# DDR16SS0_CTLPHY_WRAP_CTL_CFG_CTLCFG register map
Vendor: Texas Instruments
Registers are 32-bit, read-write, reset 0x0 unless marked. A register's access mark holds for its fields unless they carry their own. Offsets are as the file gives them; [hi:lo] are bit positions; lines under a group give offsets from that group; {n}, {i} and the like mark numbered series.

## DDR16SS0_CTLPHY_WRAP_CTL_CFG_CTLCFG (part 5 of 9)
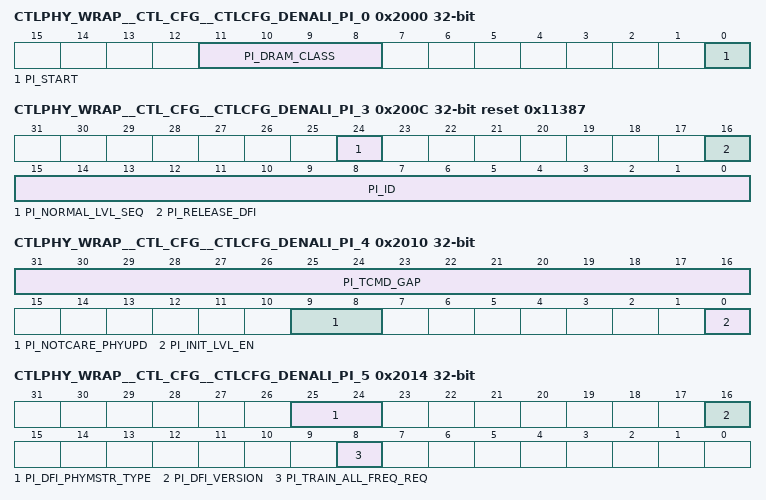
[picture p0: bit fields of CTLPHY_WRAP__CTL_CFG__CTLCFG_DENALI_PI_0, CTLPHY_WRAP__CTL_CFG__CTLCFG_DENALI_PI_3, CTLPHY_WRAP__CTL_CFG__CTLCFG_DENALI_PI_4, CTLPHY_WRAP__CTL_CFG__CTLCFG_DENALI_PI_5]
0x2000 CTLPHY_WRAP__CTL_CFG__CTLCFG_DENALI_PI_0
  [11:8] PI_DRAM_CLASS — Defines the memory class for the PI.
  [0] PI_START — Initiate command processing in the PI. Set to 1 to initiate.
0x2004 CTLPHY_WRAP__CTL_CFG__CTLCFG_DENALI_PI_1 ro reset 0xAE8D79E2
  [31:0] PI_VERSION_0 — Holds the PI version number. This is a unique number for each PHY IP delivery. This will help in identifying different version of the PHY IP. READ-ONLY
0x2008 CTLPHY_WRAP__CTL_CFG__CTLCFG_DENALI_PI_2 ro reset 0x714B570
  [31:0] PI_VERSION_1 — Holds the PI version number. This is a unique number for each PHY IP delivery. This will help in identifying different version of the PHY IP. READ-ONLY
0x200C CTLPHY_WRAP__CTL_CFG__CTLCFG_DENALI_PI_3 access per field reset 0x11387
  [24] PI_NORMAL_LVL_SEQ rw — Enable the PI to finish all the pending leveling before releasing the DFI bus.
  [16] PI_RELEASE_DFI ro — This is a status whether PI has release DFI. READ-ONLY.
  [15:0] PI_ID ro — Holds the PI ID number. This is a Cadence DDR PHY IP identifier. It is set to 0x1387. READ-ONLY
0x2010 CTLPHY_WRAP__CTL_CFG__CTLCFG_DENALI_PI_4
  [31:16] PI_TCMD_GAP — Specifies the minimum gap in DFI clocks between two commands. Used to guard the timing from the last command of MC and the first command of PI when MC hand over the control of DFI to PI.
  [9:8] PI_NOTCARE_PHYUPD — Allow the PI to issue a master request to the controller if a phyupd_req from the PHY has been detected.bit[1] represents supports in normal state;bit[0] represents supports in initialization state. Set to 1 to issue the master request.
  [0] PI_INIT_LVL_EN — Enables the initial leveling sequence after PI initialization procedure. Set to 1 to enable.
0x2014 CTLPHY_WRAP__CTL_CFG__CTLCFG_DENALI_PI_5 access per field
  [25:24] PI_DFI_PHYMSTR_TYPE rw — DFI Master Request Type used for dfi 4.1 verision: This signal indicates the required state of DRAM when PHY becomes the master. Each memory rank uses one bit. 1'b0: IDLE. The MC should close all the pages. 1'b1: IDLE or Self Refresh.
  [16] PI_DFI_VERSION rw — Define the DFI master version, set 1 for DFI4.1, set 0 for DFI4.0
  [8] PI_TRAIN_ALL_FREQ_REQ wo — Triggers training for all supported frequencies in PI_FREQ_MAP. Applies to LPDDR4 devices onlyh. Set to 1 to trigger. Only applicable after memory initialization has been completed. Can be used to train new frequencies that were not available at initialization time. WRITE-ONLY
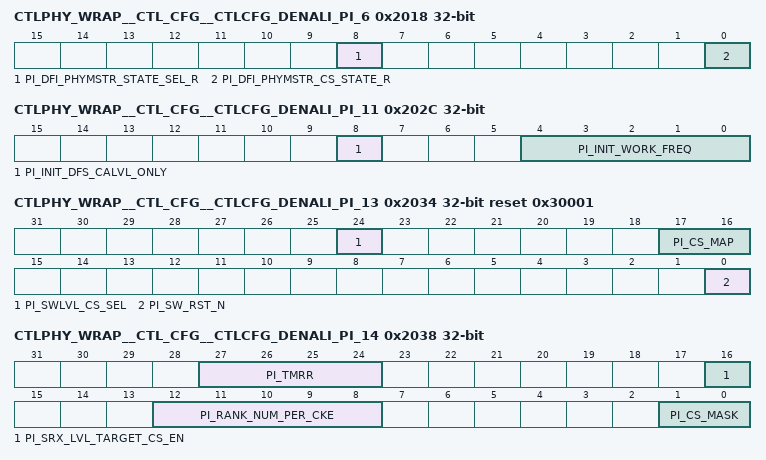
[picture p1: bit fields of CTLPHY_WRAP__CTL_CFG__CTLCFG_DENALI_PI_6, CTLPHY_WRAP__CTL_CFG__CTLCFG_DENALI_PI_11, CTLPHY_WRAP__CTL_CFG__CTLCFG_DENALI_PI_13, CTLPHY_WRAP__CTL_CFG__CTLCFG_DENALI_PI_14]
0x2018 CTLPHY_WRAP__CTL_CFG__CTLCFG_DENALI_PI_6
  [8] PI_DFI_PHYMSTR_STATE_SEL_R — DFI PHY Master State Select: Indication from the PHY to the MC whether the requested memory state is IDLE or Self refresh. 'b0: indicates that the corresponding CS must be put into the IDLE state. 'b1: indicates that the corresponding CS must be put into the Self refresh state.
  [0] PI_DFI_PHYMSTR_CS_STATE_R — This signal indicates the state of the DRAM when the PHY becomes the master. 'b0: The PHY specifies the required state, using the dfi_phymstr_state_sel signal. 'b1: is reserved.
0x201C CTLPHY_WRAP__CTL_CFG__CTLCFG_DENALI_PI_7 ro
  [31:0] PI_TDFI_PHYMSTR_MAX — Indicates the maximum number of DFI clock cycles registered while the dfi_phymstr_req signal is asserted and the dfi_phymstr_ack signal is asserted. READ-ONLY.
0x2020 CTLPHY_WRAP__CTL_CFG__CTLCFG_DENALI_PI_8 ro
  [19:0] PI_TDFI_PHYMSTR_RESP — Indicates the maximum number of DFI clock cycles registered between a dfi_phymstr_req signal assertion and a dfi_phymstr_ack signal assertion. READ-ONLY
0x2024 CTLPHY_WRAP__CTL_CFG__CTLCFG_DENALI_PI_9 ro
  [19:0] PI_TDFI_PHYUPD_RESP — Indicates the maximum number of DFI clock cycles registered between a dfi_phyupd_req signal assertion and a dfi_phyupd_ack signal assertion. READ-ONLY.
0x2028 CTLPHY_WRAP__CTL_CFG__CTLCFG_DENALI_PI_10 ro
  [31:0] PI_TDFI_PHYUPD_MAX — Indicates the maximum number of DFI clock cycles registered while the dfi_phyupd_req signal is asserted and the dfi_phy_ack signal is asserted. READ-ONLY.
0x202C CTLPHY_WRAP__CTL_CFG__CTLCFG_DENALI_PI_11
  [8] PI_INIT_DFS_CALVL_ONLY — Enables frequency training for CA leveling only. Other trainings are not performed.
  [4:0] PI_INIT_WORK_FREQ — Indicates the initial work frequency after initialization and initial leveling sequence.
0x2030 CTLPHY_WRAP__CTL_CFG__CTLCFG_DENALI_PI_12
  [31:0] PI_FREQ_MAP — Frequency map for supported working frequencies. Each bit represents one supported frequency.
0x2034 CTLPHY_WRAP__CTL_CFG__CTLCFG_DENALI_PI_13 reset 0x30001
  [24] PI_SWLVL_CS_SEL — Defines which chip selects are active in swlvl, 0 for binary, 1 for one-hot.
  [17:16] PI_CS_MAP — Defines which chip selects are active.
  [0] PI_SW_RST_N — User request to reset the whole PI except the parameter modules. Set 0 to reset, set to 1 to release.
0x2038 CTLPHY_WRAP__CTL_CFG__CTLCFG_DENALI_PI_14
  [27:24] PI_TMRR — DRAM tMRR value in memory clock cycles.
  [16] PI_SRX_LVL_TARGET_CS_EN — Defines self refresh exit trigger target rank/ranks training or all ranks training. 1: The rank/ranks exit from self refresh will trigger the corresponding rank/ranks training. Note: If multiple ranks exit from self refresh, current design only support the multiple ranks srx command issues at the same time. 0: Any rank/ranks exit from self refresh will trigger all ranks training
  [12:8] PI_RANK_NUM_PER_CKE — Defines the number of chip selects share one cke
  [1:0] PI_CS_MASK — Defines which chip selects are active.
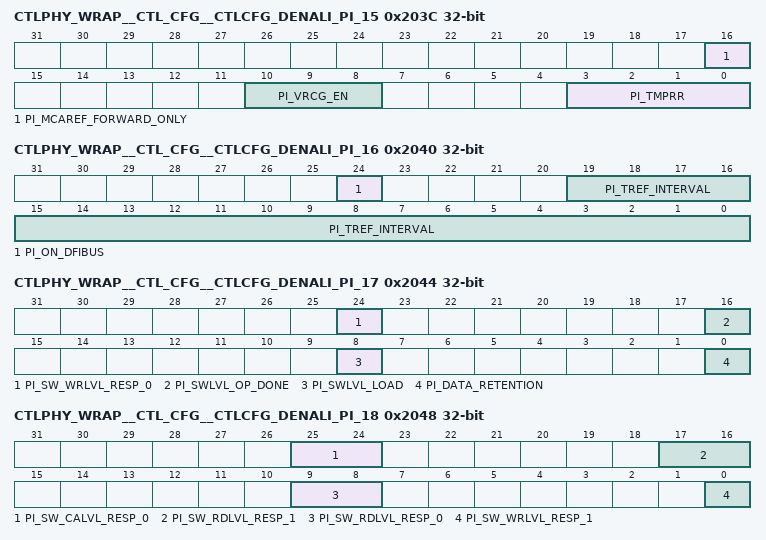
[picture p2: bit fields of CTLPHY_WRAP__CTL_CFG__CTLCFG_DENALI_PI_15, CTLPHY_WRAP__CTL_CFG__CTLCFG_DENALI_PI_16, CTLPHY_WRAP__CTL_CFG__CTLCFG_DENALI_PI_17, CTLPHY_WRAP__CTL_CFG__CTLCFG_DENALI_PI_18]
0x203C CTLPHY_WRAP__CTL_CFG__CTLCFG_DENALI_PI_15
  [16] PI_MCAREF_FORWARD_ONLY — Controls the generation of AREF from the PI module or forward the MC received value.
  [10:8] PI_VRCG_EN — Whether enable VRCG mode in two cases: bit0 - when DFS. bit1-when setting DQ Vref. bit2-when setting CBT.
  [3:0] PI_TMPRR — DRAM tMPRR value in memory clock cycles.
0x2040 CTLPHY_WRAP__CTL_CFG__CTLCFG_DENALI_PI_16 access per field
  [24] PI_ON_DFIBUS ro — Monitors the state of the PI controlling the DFI bus. 1 means PI is in control. READ-ONLY.
  [19:0] PI_TREF_INTERVAL rw — Defines the cycles between refreshes to different chip selects.
0x2044 CTLPHY_WRAP__CTL_CFG__CTLCFG_DENALI_PI_17 access per field
  [24] PI_SW_WRLVL_RESP_0 ro — Write leveling response for data slice 0. READ-ONLY
  [16] PI_SWLVL_OP_DONE ro — Reports the status of the software leveling operation. Value of 1 indicates operation complete. READ-ONLY
  [8] PI_SWLVL_LOAD wo — User request to load delays and execute software leveling. Set to 1 to trigger. WRITE-ONLY
  [0] PI_DATA_RETENTION ro — Monitors the readiness for the PHY to be put into data retention mode after pi_sref_entry req parameter has been written. 1 means ready for data retention. READ-ONLY.
0x2048 CTLPHY_WRAP__CTL_CFG__CTLCFG_DENALI_PI_18 ro
  [25:24] PI_SW_CALVL_RESP_0 — CA leveling response for address slice 0. READ-ONLY
  [17:16] PI_SW_RDLVL_RESP_1 — Read leveling response for data slice 1. READ-ONLY
  [9:8] PI_SW_RDLVL_RESP_0 — Read leveling response for data slice 0. READ-ONLY
  [0] PI_SW_WRLVL_RESP_1 — Write leveling response for data slice 1. READ-ONLY
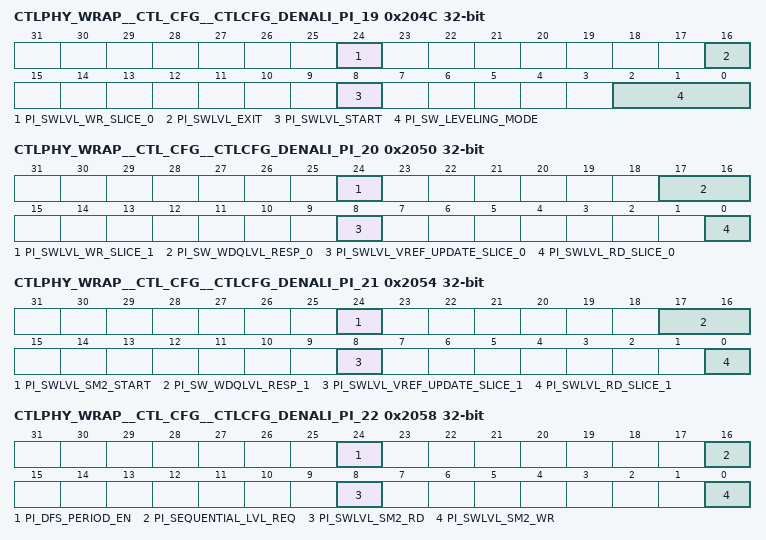
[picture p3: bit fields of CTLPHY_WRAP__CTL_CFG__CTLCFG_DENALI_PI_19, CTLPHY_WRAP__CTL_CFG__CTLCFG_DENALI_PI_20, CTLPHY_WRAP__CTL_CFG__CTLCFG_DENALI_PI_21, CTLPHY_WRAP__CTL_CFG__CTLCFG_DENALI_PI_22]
0x204C CTLPHY_WRAP__CTL_CFG__CTLCFG_DENALI_PI_19 access per field
  [24] PI_SWLVL_WR_SLICE_0 wo — SW leveling write command in WDQ training. WRITE-ONLY
  [16] PI_SWLVL_EXIT wo — User request to exit software leveling. Set to 1 to exit. WRITE-ONLY
  [8] PI_SWLVL_START wo — User request to initiate software leveling of type in the SW_LEVELING_MODE parameter. Set to 1 to trigger. WRITE-ONLY
  [2:0] PI_SW_LEVELING_MODE rw — Defines the leveling operation for software leveling. Set to 'b111 for DDR4 VREF training, set to b001 for write leveling, set to b010 for read data eye training, or set to b011 for read gate training, set to b100 for ca training, set to b101 for wdq training.
0x2050 CTLPHY_WRAP__CTL_CFG__CTLCFG_DENALI_PI_20 access per field
  [24] PI_SWLVL_WR_SLICE_1 wo — SW leveling write command in WDQ training. WRITE-ONLY
  [17:16] PI_SW_WDQLVL_RESP_0 ro — Leveling response for data slice 0. READ-ONLY
  [8] PI_SWLVL_VREF_UPDATE_SLICE_0 wo — SW leveling vref update command in WDQ training. WRITE-ONLY
  [0] PI_SWLVL_RD_SLICE_0 wo — SW leveling read command in WDQ training. WRITE-ONLY
0x2054 CTLPHY_WRAP__CTL_CFG__CTLCFG_DENALI_PI_21 access per field
  [24] PI_SWLVL_SM2_START wo — SW leveling start command for stage 2. WRITE-ONLY
  [17:16] PI_SW_WDQLVL_RESP_1 ro — Leveling response for data slice 1. READ-ONLY
  [8] PI_SWLVL_VREF_UPDATE_SLICE_1 wo — SW leveling vref update command in WDQ training. WRITE-ONLY
  [0] PI_SWLVL_RD_SLICE_1 wo — SW leveling read command in WDQ training. WRITE-ONLY
0x2058 CTLPHY_WRAP__CTL_CFG__CTLCFG_DENALI_PI_22 access per field
  [24] PI_DFS_PERIOD_EN rw — Enable the DFS triggered periodic leveling.
  [16] PI_SEQUENTIAL_LVL_REQ wo — User request to initiate all possible leveling sequences. Set to 1 to trigger. WRITE-ONLY
  [8] PI_SWLVL_SM2_RD wo — SW leveling read command for stage 2. WRITE-ONLY
  [0] PI_SWLVL_SM2_WR wo — SW leveling write command for stage 2. WRITE-ONLY
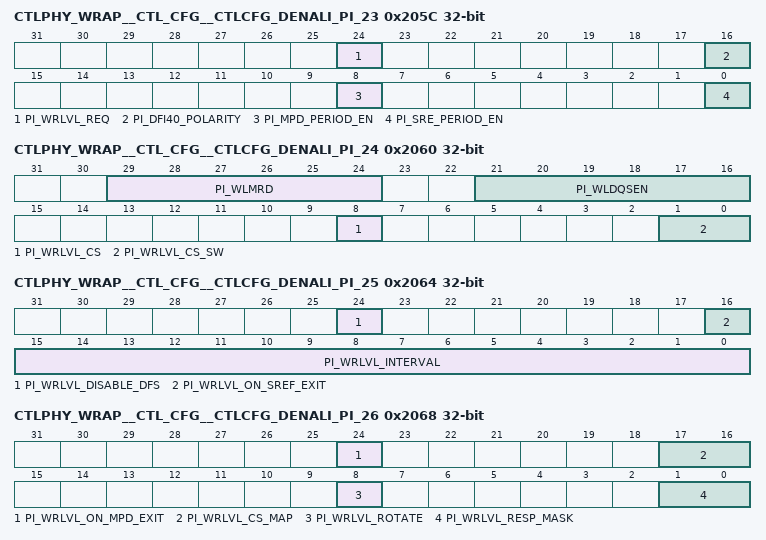
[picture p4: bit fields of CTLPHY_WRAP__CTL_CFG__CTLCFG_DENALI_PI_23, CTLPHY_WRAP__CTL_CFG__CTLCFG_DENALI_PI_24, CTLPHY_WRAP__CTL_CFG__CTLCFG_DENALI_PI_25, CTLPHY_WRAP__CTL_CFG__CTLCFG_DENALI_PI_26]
0x205C CTLPHY_WRAP__CTL_CFG__CTLCFG_DENALI_PI_23 access per field
  [24] PI_WRLVL_REQ wo — User request to initiate write leveling. Set to 1 to trigger. WRITE-ONLY
  [16] PI_DFI40_POLARITY rw — Defines the polarity of the dfi_wrdata_cs_n/dfi_rddata_cs_n signals.
  [8] PI_MPD_PERIOD_EN rw — Enable the max power saving mode exit triggered periodic leveling.
  [0] PI_SRE_PERIOD_EN rw — Enable the self refresh exit triggered periodic leveling.
0x2060 CTLPHY_WRAP__CTL_CFG__CTLCFG_DENALI_PI_24
  [29:24] PI_WLMRD — Delay from issuing MRS to first write leveling strobe.
  [21:16] PI_WLDQSEN — Delay from issuing MRS to first DQS strobe for write leveling.
  [8] PI_WRLVL_CS — Specifies the target chip select for the write leveling operation initiated through the WRLVL_REQ parameter.
  [1:0] PI_WRLVL_CS_SW — Specifies the target chip select for the write leveling operation initiated through the WRLVL_REQ parameter.
0x2064 CTLPHY_WRAP__CTL_CFG__CTLCFG_DENALI_PI_25
  [24] PI_WRLVL_DISABLE_DFS — Disable automatic write leveling on freq change. Set to 1 to disable wrlvl on dfs,set 0 enable wrlvl on dfs.
  [16] PI_WRLVL_ON_SREF_EXIT — Enables automatic write leveling on a self-refresh exit. Set to 1 to enable.
  [15:0] PI_WRLVL_INTERVAL — Number of long count sequences counted between automatic write leveling commands.
0x2068 CTLPHY_WRAP__CTL_CFG__CTLCFG_DENALI_PI_26
  [24] PI_WRLVL_ON_MPD_EXIT — Enables automatic write leveling on a maximum power down mode exit. Set to 1 to enable.
  [17:16] PI_WRLVL_CS_MAP — Defines the chip select map for write leveling operations. Bit [0] controls cs0, bit [1] controls cs1, etc. Set each bit to 1 to enable chip for write leveling.
  [8] PI_WRLVL_ROTATE — Enables rotational CS for counter triggered automatic write leveling. Set to 1, only one rank's write levling will process, the rank number is rotational for each time that write leveling been triggered by counter expiring. Set to 0 or not a short pattern leveling [indicated by dfi_lvl_periodic], the counter expired write leveling will process all the ranks.
  [1:0] PI_WRLVL_RESP_MASK — Mask for the dfi_wrlvl_resp signal during write leveling.
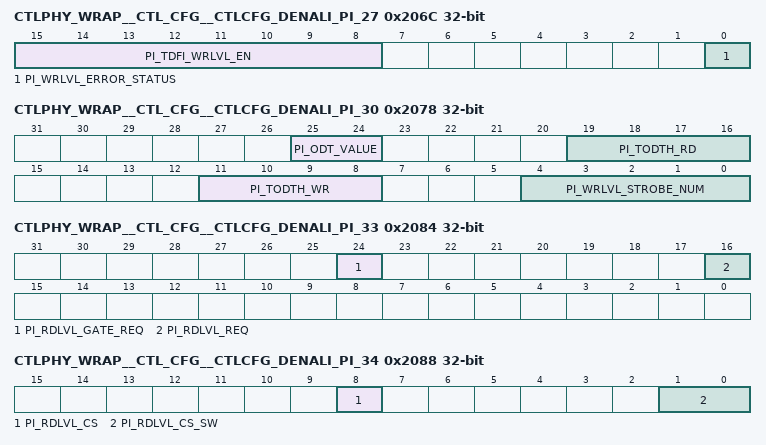
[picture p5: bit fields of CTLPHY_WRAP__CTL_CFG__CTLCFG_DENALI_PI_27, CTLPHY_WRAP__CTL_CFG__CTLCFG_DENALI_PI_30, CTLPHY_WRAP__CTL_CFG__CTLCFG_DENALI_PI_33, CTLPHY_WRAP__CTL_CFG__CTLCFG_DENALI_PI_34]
0x206C CTLPHY_WRAP__CTL_CFG__CTLCFG_DENALI_PI_27 access per field
  [15:8] PI_TDFI_WRLVL_EN rw — Defines the DFI tWRLVL_EN timing parameter [in DFI clocks], the minimum cycles from a dfi_wrlvl_en assertion to the first dfi_wrlvl_strobe assertion.
  [0] PI_WRLVL_ERROR_STATUS ro — Holds the error associated with the write level error interrupt. Bit [0] set indicates a TDFI_WRLVL_MAX parameter violation and bit [1] set indicates a TDFI_WRLVL_RESP parameter violation. READ-ONLY
0x2070 CTLPHY_WRAP__CTL_CFG__CTLCFG_DENALI_PI_28
  [31:0] PI_TDFI_WRLVL_RESP — Defines the DFI tWRLVL_RESP timing parameter [in DFI clocks], the maximum cycles between a dfi_wrlvl_req assertion and a dfi_wrlvl_en assertion.
0x2074 CTLPHY_WRAP__CTL_CFG__CTLCFG_DENALI_PI_29
  [31:0] PI_TDFI_WRLVL_MAX — Defines the DFI tWRLVL_MAX timing parameter [in DFI clocks], the maximum cycles between a dfi_wrlvl_en assertion and a valid dfi_wrlvl_resp.
0x2078 CTLPHY_WRAP__CTL_CFG__CTLCFG_DENALI_PI_30
  [25:24] PI_ODT_VALUE — When using LPDDR4, this value will be driven out on the dfi_odt signal.
  [19:16] PI_TODTH_RD — Defines the minimum DRAM cycles of ODT high time for a read command, in memory clocks.
  [11:8] PI_TODTH_WR — Defines the minimum DRAM cycles of ODT high time for a write command, in memory clocks.
  [4:0] PI_WRLVL_STROBE_NUM — Defines the number of write leveling strobes generated.
0x207C CTLPHY_WRAP__CTL_CFG__CTLCFG_DENALI_PI_31
  [1:0] PI_ADDRESS_MIRRORING — Indicates which chip selects support address mirroring. Bit [0] controls cs0, bit [1] controls cs1, etc. Set each bit to 1 to enable.
0x2080 CTLPHY_WRAP__CTL_CFG__CTLCFG_DENALI_PI_32
  [25:0] PI_CA_PARITY_ERROR_INJECT — Selects bit to corrupt on the CA bus for CA parity error injection.
0x2084 CTLPHY_WRAP__CTL_CFG__CTLCFG_DENALI_PI_33 wo
  [24] PI_RDLVL_GATE_REQ — User request to initiate gate training. Set to 1 to trigger. WRITE-ONLY
  [16] PI_RDLVL_REQ — User request to initiate data eye training. Set to 1 to trigger. WRITE-ONLY
0x2088 CTLPHY_WRAP__CTL_CFG__CTLCFG_DENALI_PI_34
  [8] PI_RDLVL_CS — Specifies the target chip select for the data eye training operation initiated through the RDLVL_REQ parameter or the gate training operation initiated through the RDLVL_GATE_REQ parameter.
  [1:0] PI_RDLVL_CS_SW — Specifies the target chip select for the data eye training operation initiated through the RDLVL_REQ parameter or the gate training operation initiated through the RDLVL_GATE_REQ parameter.
{0x2000+4i} CTLPHY_WRAP__CTL_CFG__CTLCFG_DENALI_PI_{i} (i=35..42)
  [31:0] PI_RDLVL_PAT_{i-35} — Non-default pattern {i-35} used for read data eye training of DDR4 or LPDDR4, and read dbi training of DDR4.
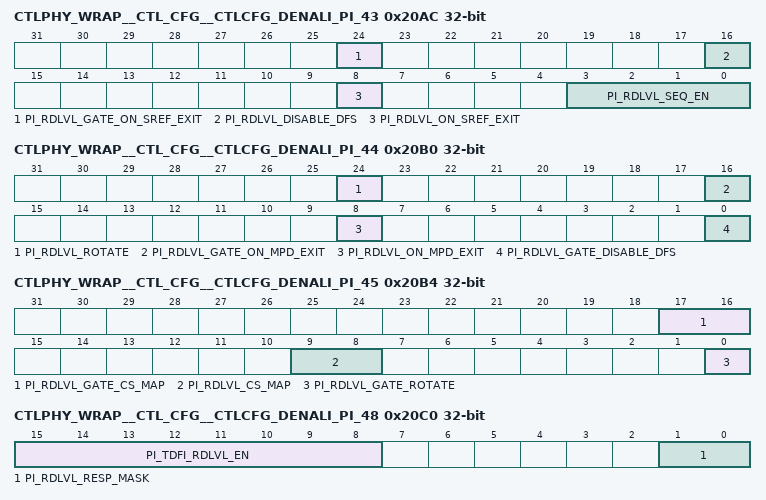
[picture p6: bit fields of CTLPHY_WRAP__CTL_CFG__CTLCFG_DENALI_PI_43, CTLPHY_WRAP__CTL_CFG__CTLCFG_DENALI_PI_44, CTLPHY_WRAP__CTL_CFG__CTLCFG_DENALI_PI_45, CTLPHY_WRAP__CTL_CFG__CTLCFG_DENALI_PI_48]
0x20AC CTLPHY_WRAP__CTL_CFG__CTLCFG_DENALI_PI_43
  [24] PI_RDLVL_GATE_ON_SREF_EXIT — Enables automatic gate training on a self-refresh exit. Set to 1 to enable.
  [16] PI_RDLVL_DISABLE_DFS — Disables automatic data eye training on freq change. Set to 1 to disable rdlvl on dfs,Set to 0 to enable rdlvl on dfs.
  [8] PI_RDLVL_ON_SREF_EXIT — Enables automatic data eye training on a self-refresh exit. Set to 1 to enable.
  [3:0] PI_RDLVL_SEQ_EN — Specifies the pattern, format and MPR for data eye training.
0x20B0 CTLPHY_WRAP__CTL_CFG__CTLCFG_DENALI_PI_44
  [24] PI_RDLVL_ROTATE — Enables rotational CS for interval data eye training. Set to 1 for rotating CS.
  [16] PI_RDLVL_GATE_ON_MPD_EXIT — Enables automatic gate training on a maximum power down mode exit. Set to 1 to enable.
  [8] PI_RDLVL_ON_MPD_EXIT — Enables automatic data eye training on a maximum power down mode exit. Set to 1 to enable.
  [0] PI_RDLVL_GATE_DISABLE_DFS — Disables automatic gate training on freq change. Set to 1 to disable rdlvl_gate on dfs,Set to 0 to enable rdlvl_gate on dfs.
0x20B4 CTLPHY_WRAP__CTL_CFG__CTLCFG_DENALI_PI_45
  [17:16] PI_RDLVL_GATE_CS_MAP — Defines the chip select map for gate training operations. Bit [0] controls cs0, bit [1] controls cs1, etc. Set each bit to 1 to enable chip for gate training.
  [9:8] PI_RDLVL_CS_MAP — Defines the chip select map for data eye training operations. Bit [0] controls cs0, bit [1] controls cs1, etc. Set each bit to 1 to enable chip for data eye training.
  [0] PI_RDLVL_GATE_ROTATE — Enables rotational CS for interval gate training. Set to 1 for rotating CS.
0x20B8 CTLPHY_WRAP__CTL_CFG__CTLCFG_DENALI_PI_46
  [9:0] PI_TDFI_RDLVL_RR — Defines the DFI tRDLVL_RR timing parameter [in DFI clocks], the minimum cycles between read commands.
0x20BC CTLPHY_WRAP__CTL_CFG__CTLCFG_DENALI_PI_47
  [31:0] PI_TDFI_RDLVL_RESP — Defines the DFI tRDLVL_RESP timing parameter [in DFI clocks], the maximum cycles between a dfi_rdlvl_req or dfi_rdlvl_gate_req assertion and a dfi_rdlvl_en or dfi_rdlvl_gate_en assertion.
0x20C0 CTLPHY_WRAP__CTL_CFG__CTLCFG_DENALI_PI_48
  [15:8] PI_TDFI_RDLVL_EN — Defines the DFI tRDLVL_EN timing parameter [in DFI clocks], the minimum cycles from a dfi_rdlvl_en or dfi_rdlvl_gate_en assertion to the first read or MRR. Set to 1 means the minium value[1 cycle], set to 0 means the maxium value
  [1:0] PI_RDLVL_RESP_MASK — Mask for the dfi_rdlvl_resp signal during data eye training.
0x20C4 CTLPHY_WRAP__CTL_CFG__CTLCFG_DENALI_PI_49
  [31:0] PI_TDFI_RDLVL_MAX — Defines the DFI tRDLVL_MAX timing parameter [in DFI clocks], the maximum cycles between a dfi_rdlvl_en or dfi_rdlvl_gate_en assertion and a valid dfi_rdlvl_resp.
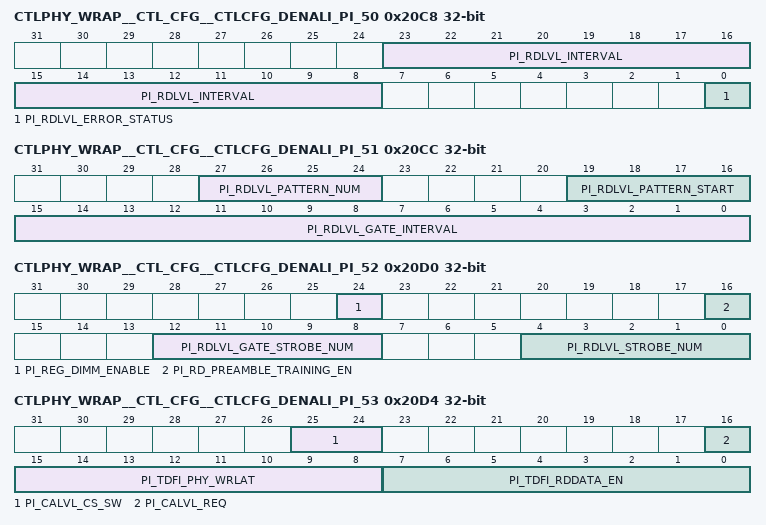
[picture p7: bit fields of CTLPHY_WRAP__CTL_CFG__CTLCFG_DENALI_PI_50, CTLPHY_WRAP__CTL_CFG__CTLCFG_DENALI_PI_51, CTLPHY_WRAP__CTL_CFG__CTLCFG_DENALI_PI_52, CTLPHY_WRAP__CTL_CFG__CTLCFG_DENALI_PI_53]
0x20C8 CTLPHY_WRAP__CTL_CFG__CTLCFG_DENALI_PI_50 access per field
  [23:8] PI_RDLVL_INTERVAL rw — Number of long count sequences counted between automatic data eye training commands.
  [0] PI_RDLVL_ERROR_STATUS ro — Holds the error associated with the data eye training error or gate training error interrupt. Uppermost bit set indicates a TDFI_RDLVL_RESP parameter violation. Next uppermost bit set indicates a TDFI_RDLVL_MAX parameter violation. Lower bits are reserved. READ-ONLY
0x20CC CTLPHY_WRAP__CTL_CFG__CTLCFG_DENALI_PI_51
  [27:24] PI_RDLVL_PATTERN_NUM — Defines the number of pattern supported in read leveling.
  [19:16] PI_RDLVL_PATTERN_START — Defines the start pattern in read leveling.
  [15:0] PI_RDLVL_GATE_INTERVAL — Number of long count sequences counted between automatic gate training commands.
0x20D0 CTLPHY_WRAP__CTL_CFG__CTLCFG_DENALI_PI_52
  [24] PI_REG_DIMM_ENABLE — Enable registered DIMM operation. Set to 1 to enable.
  [16] PI_RD_PREAMBLE_TRAINING_EN — Enable read preamble training during gate training. Set to 1 to enable.
  [12:8] PI_RDLVL_GATE_STROBE_NUM — Defines the number of back to back MPC command in one read process in read gate training.
  [4:0] PI_RDLVL_STROBE_NUM — Defines the number of back to back MPC command in one read process in read eye training.
0x20D4 CTLPHY_WRAP__CTL_CFG__CTLCFG_DENALI_PI_53 access per field
  [25:24] PI_CALVL_CS_SW rw — Specifies the target chip select for the CA training operation initiated through the CALVL_REQ parameter.
  [16] PI_CALVL_REQ wo — User request to initiate CA training. Set to 1 to trigger. WRITE-ONLY
  [15:8] PI_TDFI_PHY_WRLAT ro — Holds the calculated DFI tPHY_WRLAT timing parameter [in DFI PHY clocks], the maximum cycles between a write command and a dfi_wrdata_en assertion. READ-ONLY
  [7:0] PI_TDFI_RDDATA_EN ro — Holds the calculated DFI tRDDATA_EN timing parameter [in DFI PHY clocks], the maximum cycles between a read command and a dfi_rddata_en assertion. READ-ONLY
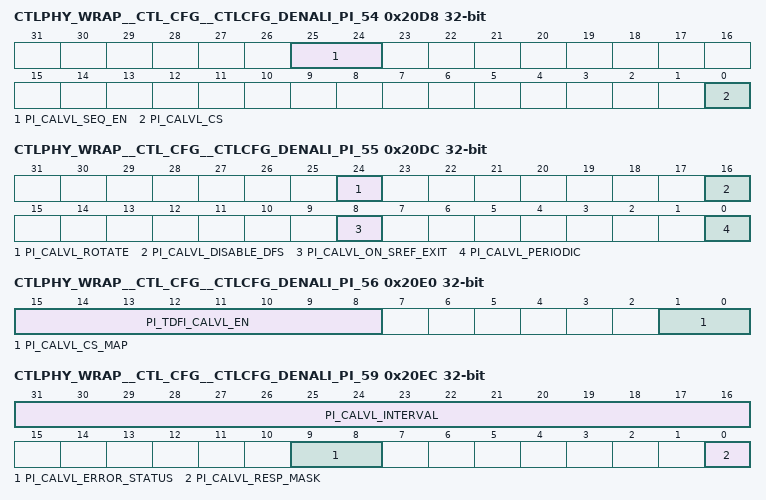
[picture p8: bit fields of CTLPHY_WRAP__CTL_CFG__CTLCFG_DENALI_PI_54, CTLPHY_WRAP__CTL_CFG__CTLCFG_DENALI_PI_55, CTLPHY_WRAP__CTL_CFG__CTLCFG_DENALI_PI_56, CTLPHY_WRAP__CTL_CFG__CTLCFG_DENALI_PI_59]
0x20D8 CTLPHY_WRAP__CTL_CFG__CTLCFG_DENALI_PI_54
  [25:24] PI_CALVL_SEQ_EN — Specifies which CA training patterns will be used. Set to 0 for pattern 0 only, set to 1 for patterns 0 and 1, set to 2 for patterns 0, 1 and 2, or set to 3 for all patterns.
  [0] PI_CALVL_CS — Specifies the target chip select for the CA training operation initiated through the CALVL_REQ parameter.
0x20DC CTLPHY_WRAP__CTL_CFG__CTLCFG_DENALI_PI_55
  [24] PI_CALVL_ROTATE — Enables rotational CS for interval CA training. Set to 1 for rotating CS.
  [16] PI_CALVL_DISABLE_DFS — Disables automatic CA training on freq change. Set to 1 to disable CA training on dfs, Set to 0 to enable CA training .
  [8] PI_CALVL_ON_SREF_EXIT — Enables automatic CA training on a self-refresh exit. Set to 1 to enable.
  [0] PI_CALVL_PERIODIC — Enables the use of the dfi_lvl_periodic signal during CA training. Set to 1 to enable.
0x20E0 CTLPHY_WRAP__CTL_CFG__CTLCFG_DENALI_PI_56
  [15:8] PI_TDFI_CALVL_EN — Defines the DFI tCALVL_EN timing parameter [in DFI clocks], the minimum cycles between a dfi_calvl_en assertion and a dfi_cke de-assertion.
  [1:0] PI_CALVL_CS_MAP — Defines the chip select map for CA training operations. Bit [0] controls cs0, bit [1] controls cs1, etc. Set each bit to 1 to enable chip for CA training.
0x20E4 CTLPHY_WRAP__CTL_CFG__CTLCFG_DENALI_PI_57
  [31:0] PI_TDFI_CALVL_RESP — Defines the DFI tCALVL_RESP timing parameter [in DFI clocks], the maximum cycles between a dfi_calvl_req assertion and a dfi_calvl_en assertion.
0x20E8 CTLPHY_WRAP__CTL_CFG__CTLCFG_DENALI_PI_58
  [31:0] PI_TDFI_CALVL_MAX — Defines the DFI tCALVL_MAX timing parameter [in DFI clocks], the maximum cycles between a dfi_calvl_en assertion and a valid dfi_calvl_resp.
0x20EC CTLPHY_WRAP__CTL_CFG__CTLCFG_DENALI_PI_59 access per field
  [31:16] PI_CALVL_INTERVAL rw — Number of long count sequences counted between automatic CA training commands.
  [9:8] PI_CALVL_ERROR_STATUS ro — Holds the error associated with the CA training error interrupt. Bit [0] set indicates a TDFI_CALVL_RESP parameter violation and bit [1] set indicates a TDFI_CALVL_MAX parameter violation. READ-ONLY
  [0] PI_CALVL_RESP_MASK rw — Mask for the dfi_calvl_resp signal during CA training.
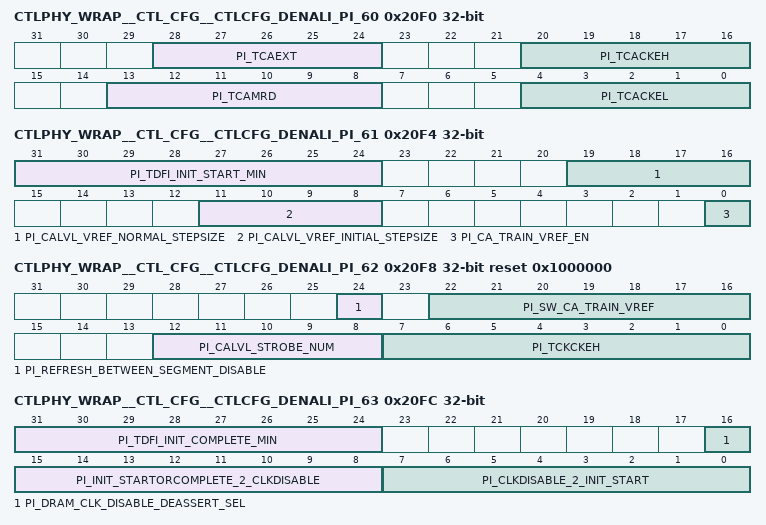
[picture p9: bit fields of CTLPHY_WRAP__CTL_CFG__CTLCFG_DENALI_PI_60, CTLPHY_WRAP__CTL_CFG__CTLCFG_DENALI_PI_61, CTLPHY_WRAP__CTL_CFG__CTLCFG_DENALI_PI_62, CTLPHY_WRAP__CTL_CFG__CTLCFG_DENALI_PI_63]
0x20F0 CTLPHY_WRAP__CTL_CFG__CTLCFG_DENALI_PI_60
  [28:24] PI_TCAEXT — DRAM tCAEXT value in memory cycles.
  [20:16] PI_TCACKEH — DRAM tCACKEH value in memory cycles.
  [13:8] PI_TCAMRD — DRAM tCAMRD value in memory cycles.
  [4:0] PI_TCACKEL — DRAM tCACKEL value in memory cycles.
0x20F4 CTLPHY_WRAP__CTL_CFG__CTLCFG_DENALI_PI_61
  [31:24] PI_TDFI_INIT_START_MIN — Minimum number of DFI clocks before dfi_init_start can be driven after a previous command/training event.
  [19:16] PI_CALVL_VREF_NORMAL_STEPSIZE — The adjust step for the post-initial Vref[ca] training.
  [11:8] PI_CALVL_VREF_INITIAL_STEPSIZE — The adjust step for the initial Vref[ca] training.
  [0] PI_CA_TRAIN_VREF_EN — Control for VREF training during CA training post power-on initialization. Set to enable VREF training.
0x20F8 CTLPHY_WRAP__CTL_CFG__CTLCFG_DENALI_PI_62 reset 0x1000000
  [24] PI_REFRESH_BETWEEN_SEGMENT_DISABLE — Disable the refresh between CA first and second segment training. Set to 1 to disable.
  [22:16] PI_SW_CA_TRAIN_VREF — The Vref value which is set for SW step by step CA training.
  [12:8] PI_CALVL_STROBE_NUM — The consecutive dfi_calvl_strobe number when updating the CA vref data.
  [7:0] PI_TCKCKEH — DRAM tCKELCK Clock and command valid before CKE HIGH.
0x20FC CTLPHY_WRAP__CTL_CFG__CTLCFG_DENALI_PI_63
  [31:24] PI_TDFI_INIT_COMPLETE_MIN — Minimum number of DFI clocks from dfi_init_complete to a command/training event.
  [16] PI_DRAM_CLK_DISABLE_DEASSERT_SEL — Indicate dfi_dram_clk_disable deassert following dfi_init_start deassert or dfi_init_complete assert. Set to 0: dfi_dram_clk_disable deassert following dfi_init_start deassert. Set to 1: dfi_dram_clk_disable deassert following dfi_init_complete assert.
  [15:8] PI_INIT_STARTORCOMPLETE_2_CLKDISABLE — Defines the delay from deasserting of dfi_init_start or asserting of dfi_init_complete to deasserting of dfi_dram_clk_disable in DFI clock.
  [7:0] PI_CLKDISABLE_2_INIT_START — Defines the delay from the asserting of dfi_dram_clk_disable to the asserting of dfi_init_start in DFI clock.
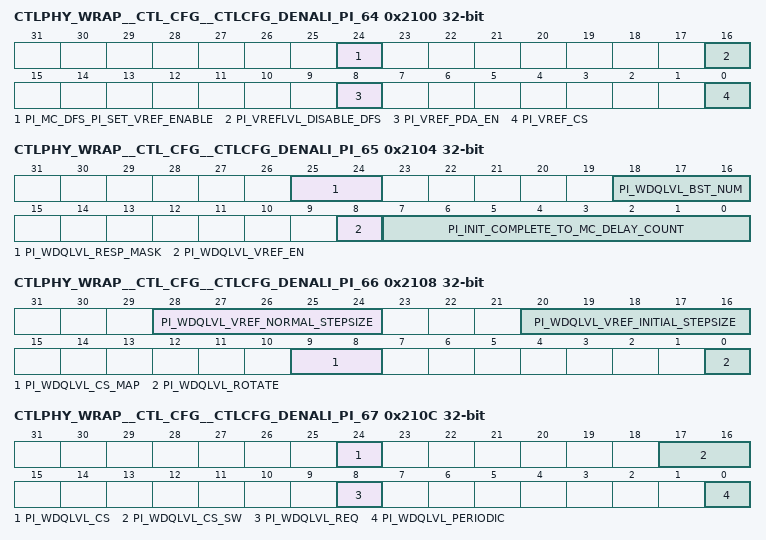
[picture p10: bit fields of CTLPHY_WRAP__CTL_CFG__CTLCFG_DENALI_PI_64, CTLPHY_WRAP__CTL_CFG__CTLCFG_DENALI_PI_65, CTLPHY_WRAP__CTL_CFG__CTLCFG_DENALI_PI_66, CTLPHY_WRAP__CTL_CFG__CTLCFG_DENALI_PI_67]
0x2100 CTLPHY_WRAP__CTL_CFG__CTLCFG_DENALI_PI_64
  [24] PI_MC_DFS_PI_SET_VREF_ENABLE — Enable the PI to set VREF value after DFS issued by MC. MR12 and MR14 for LPDDR4. MR6 for DDR4. 1 means disable.
  [16] PI_VREFLVL_DISABLE_DFS — Disables automatic VREF training on freq change. Set to 1 to disable.
  [8] PI_VREF_PDA_EN — Enable per-DRAM addressability during VREF training. Set to 1 to enable.
  [0] PI_VREF_CS — Specifies the target chip select for the VREF training operation.
0x2104 CTLPHY_WRAP__CTL_CFG__CTLCFG_DENALI_PI_65
  [25:24] PI_WDQLVL_RESP_MASK — Write DQ training response mask. When set to 1, the dfi_wdqlvl_en of the slice is not asserted.
  [18:16] PI_WDQLVL_BST_NUM — Defines the number of write/read bursts issued at each step in write DQ training.
  [8] PI_WDQLVL_VREF_EN — Control for VREF training as part of non-initialization write DQ training.
  [7:0] PI_INIT_COMPLETE_TO_MC_DELAY_COUNT — It controls the time PI bypass CKE at the beginning of PI mask dfi_init_complete to controller.
0x2108 CTLPHY_WRAP__CTL_CFG__CTLCFG_DENALI_PI_66
  [28:24] PI_WDQLVL_VREF_NORMAL_STEPSIZE — Write DQ training vref step size for post_initial training.
  [20:16] PI_WDQLVL_VREF_INITIAL_STEPSIZE — Write DQ training vref step size for initial training.
  [9:8] PI_WDQLVL_CS_MAP — Map of CS's included in write DQ training sequence.
  [0] PI_WDQLVL_ROTATE — Enables write DQ training rotate for interval training.
0x210C CTLPHY_WRAP__CTL_CFG__CTLCFG_DENALI_PI_67 access per field
  [24] PI_WDQLVL_CS rw — Write DQ training target chip select.
  [17:16] PI_WDQLVL_CS_SW rw — Write DQ training target chip select.
  [8] PI_WDQLVL_REQ wo — SW write to initiate Write DQ training request. WRITE-ONLY
  [0] PI_WDQLVL_PERIODIC rw — Enables periodic write DQ training.
0x2110 CTLPHY_WRAP__CTL_CFG__CTLCFG_DENALI_PI_68
  [7:0] PI_TDFI_WDQLVL_EN — DFI timing param tWDQLVL_EN. Minimum number of DFI clocks required after the write DQ training enable signal is asserted until the first write command may be asserted.
0x2114 CTLPHY_WRAP__CTL_CFG__CTLCFG_DENALI_PI_69
  [31:0] PI_TDFI_WDQLVL_RESP — DFI timing param tWDQLVL_RESP. Maximum number of DFI clocks that may occur between a write DQ training request and the associated mode enable.
0x2118 CTLPHY_WRAP__CTL_CFG__CTLCFG_DENALI_PI_70
  [31:0] PI_TDFI_WDQLVL_MAX — DFI timing param tWDQLVL_MAX. Maximum number of DFI clocks that the PI will wait for a response from the PHY.
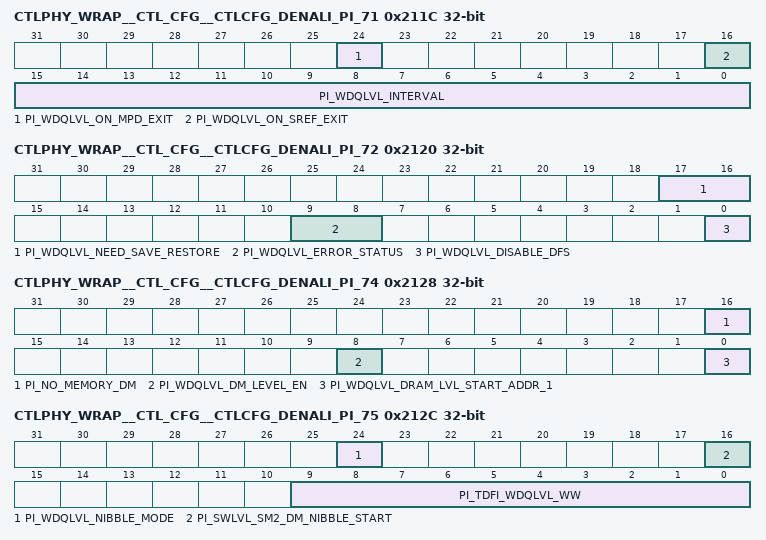
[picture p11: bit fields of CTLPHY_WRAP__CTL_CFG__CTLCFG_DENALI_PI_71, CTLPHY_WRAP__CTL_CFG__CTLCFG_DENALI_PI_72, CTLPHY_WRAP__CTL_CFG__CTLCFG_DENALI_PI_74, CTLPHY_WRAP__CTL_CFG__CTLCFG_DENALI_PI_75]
0x211C CTLPHY_WRAP__CTL_CFG__CTLCFG_DENALI_PI_71
  [24] PI_WDQLVL_ON_MPD_EXIT — Issue a write DQ training command on maximum power saving mode exit.
  [16] PI_WDQLVL_ON_SREF_EXIT — Issue a write DQ training command on self-refresh exit.
  [15:0] PI_WDQLVL_INTERVAL — Sets the maximum number of long count sequences allowed between automatic write DQ training operations.
0x2120 CTLPHY_WRAP__CTL_CFG__CTLCFG_DENALI_PI_72 access per field
  [17:16] PI_WDQLVL_NEED_SAVE_RESTORE rw — Enables the use of functional DRAM address space for write DQ training, 1 = enable, not for LPDDR4.
  [9:8] PI_WDQLVL_ERROR_STATUS ro — Holds the error associated with the write dq level error interrupt. Bit [0] set indicates a PI_TDFI_WDQLVL_MAX parameter violation and bit [1] set indicates a PI_TDFI_WDQLVL_RESP parameter violation. READ-ONLY.
  [0] PI_WDQLVL_DISABLE_DFS rw — Disable automatic write DQ training on freq change. Set to 1 to disable.
0x2124 CTLPHY_WRAP__CTL_CFG__CTLCFG_DENALI_PI_73
  [31:0] PI_WDQLVL_DRAM_LVL_START_ADDR_0 — Start address of WDQ leveling, not for LPDDR4.
0x2128 CTLPHY_WRAP__CTL_CFG__CTLCFG_DENALI_PI_74
  [16] PI_NO_MEMORY_DM — Defines if the attached memory supports the Data Mask function, 1 = not supported.
  [8] PI_WDQLVL_DM_LEVEL_EN — Enable for write DM training as part of the write DQ training, not for LPDDR4.
  [0] PI_WDQLVL_DRAM_LVL_START_ADDR_1 — Start address of WDQ leveling, not for LPDDR4.
0x212C CTLPHY_WRAP__CTL_CFG__CTLCFG_DENALI_PI_75 access per field
  [24] PI_WDQLVL_NIBBLE_MODE rw — WDQ Training Nibble mode indication. When set to 1, nibble mode is enabled, and the training timing is doubled.
  [16] PI_SWLVL_SM2_DM_NIBBLE_START wo — Start command for stage 2, when in the process of DM leveling or nibble mode. WRITE-ONLY
  [9:0] PI_TDFI_WDQLVL_WW rw — Minimum number of DFI clocks to be inserted between write commands during the DM portion of write DQ training.
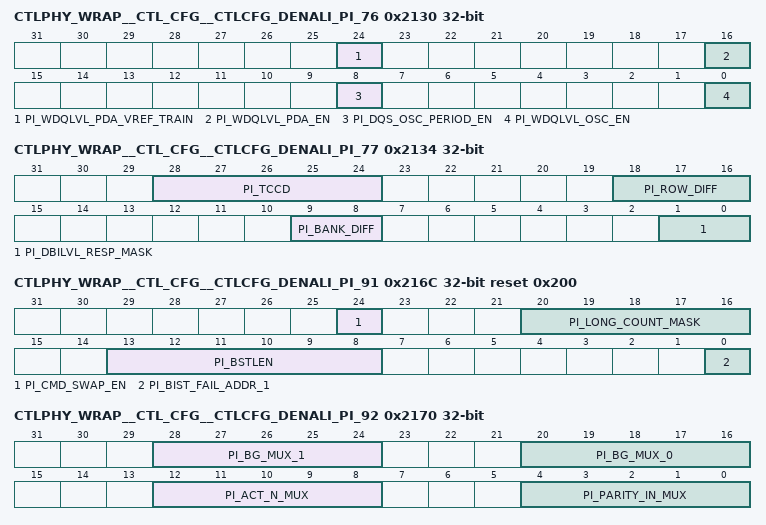
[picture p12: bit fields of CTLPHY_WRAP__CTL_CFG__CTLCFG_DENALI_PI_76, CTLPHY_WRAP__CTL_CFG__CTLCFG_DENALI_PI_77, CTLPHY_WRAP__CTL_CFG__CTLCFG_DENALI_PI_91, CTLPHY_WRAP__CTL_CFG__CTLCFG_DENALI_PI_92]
0x2130 CTLPHY_WRAP__CTL_CFG__CTLCFG_DENALI_PI_76
  [24] PI_WDQLVL_PDA_VREF_TRAIN — Enable for the use of PDA to set the VREF during write DQ training, 1 = enabled.
  [16] PI_WDQLVL_PDA_EN — Enable for the use of write DQ training for PDA mode, 1 = enabled.
  [8] PI_DQS_OSC_PERIOD_EN — Enable for DQS oscillator triggered periodic write DQ training, 1 = enabled.
  [0] PI_WDQLVL_OSC_EN — Enable for DQS oscillator triggered write DQ training, 1 = enabled.
0x2134 CTLPHY_WRAP__CTL_CFG__CTLCFG_DENALI_PI_77
  [28:24] PI_TCCD — DRAM CAS-to-CAS value in cycles.
  [18:16] PI_ROW_DIFF — Difference between number of address pins available and number being used.
  [9:8] PI_BANK_DIFF — Difference between number of bank pins available and number being used.
  [1:0] PI_DBILVL_RESP_MASK — Mask for the dfi_rdlvl_resp signal during read dbi training.
{0x2000+4i} CTLPHY_WRAP__CTL_CFG__CTLCFG_DENALI_PI_{i} access not given reset not defined (i=78..82)
0x214C CTLPHY_WRAP__CTL_CFG__CTLCFG_DENALI_PI_83 ro
  [29:0] PI_INT_STATUS — Status of interrupt features in the PI. READ-ONLY
0x2150 CTLPHY_WRAP__CTL_CFG__CTLCFG_DENALI_PI_84 wo
  [28:0] PI_INT_ACK — Clear the corresponding interrupt bit of the PI_INT_STATUS parameter. WRITE-ONLY
0x2154 CTLPHY_WRAP__CTL_CFG__CTLCFG_DENALI_PI_85
  [29:0] PI_INT_MASK — Mask for PI_int signals from the PI_INT_STATUS parameter.
0x2158 CTLPHY_WRAP__CTL_CFG__CTLCFG_DENALI_PI_86 ro
  [31:0] PI_BIST_EXP_DATA_0 — Expected data on BIST error. READ-ONLY
0x215C CTLPHY_WRAP__CTL_CFG__CTLCFG_DENALI_PI_87 ro
  [31:0] PI_BIST_EXP_DATA_1 — Expected data on BIST error. READ-ONLY
0x2160 CTLPHY_WRAP__CTL_CFG__CTLCFG_DENALI_PI_88 ro
  [31:0] PI_BIST_FAIL_DATA_0 — Actual data on BIST error. READ-ONLY
0x2164 CTLPHY_WRAP__CTL_CFG__CTLCFG_DENALI_PI_89 ro
  [31:0] PI_BIST_FAIL_DATA_1 — Actual data on BIST error. READ-ONLY
0x2168 CTLPHY_WRAP__CTL_CFG__CTLCFG_DENALI_PI_90 ro
  [31:0] PI_BIST_FAIL_ADDR_0 — The burst aligned address of BIST error. READ-ONLY
0x216C CTLPHY_WRAP__CTL_CFG__CTLCFG_DENALI_PI_91 access per field reset 0x200
  [24] PI_CMD_SWAP_EN rw — Command pin swap function enable
  [20:16] PI_LONG_COUNT_MASK rw — Reduces the length of the long counter from 1024 cycles.
  [13:8] PI_BSTLEN rw — Encoded burst length sent to DRAMs during initialization.
  [0] PI_BIST_FAIL_ADDR_1 ro — The burst aligned address of BIST error. READ-ONLY
0x2170 CTLPHY_WRAP__CTL_CFG__CTLCFG_DENALI_PI_92
  [28:24] PI_BG_MUX_1 — Command pin BG_1 mux selector
  [20:16] PI_BG_MUX_0 — Command pin BG_0 mux selector
  [12:8] PI_ACT_N_MUX — Command pin ACT_N mux selector
  [4:0] PI_PARITY_IN_MUX — Command pin parity mux selector
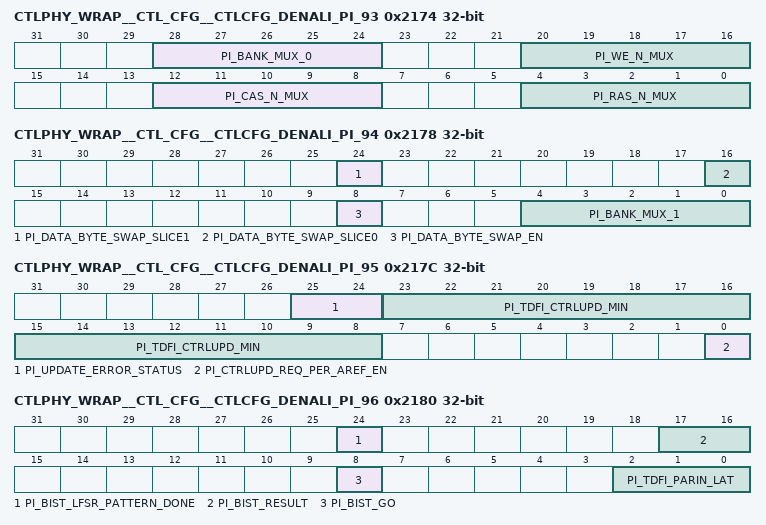
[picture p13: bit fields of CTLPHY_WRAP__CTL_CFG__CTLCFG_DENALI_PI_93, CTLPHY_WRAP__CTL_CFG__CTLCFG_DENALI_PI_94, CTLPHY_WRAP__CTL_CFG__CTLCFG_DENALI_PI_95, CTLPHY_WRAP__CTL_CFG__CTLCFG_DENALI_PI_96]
0x2174 CTLPHY_WRAP__CTL_CFG__CTLCFG_DENALI_PI_93
  [28:24] PI_BANK_MUX_0 — Command pin BANK_0 mux selector
  [20:16] PI_WE_N_MUX — Command pin WE_N mux selector
  [12:8] PI_CAS_N_MUX — Command pin CAS_N mux selector
  [4:0] PI_RAS_N_MUX — Command pin RAS_N mux selector
0x2178 CTLPHY_WRAP__CTL_CFG__CTLCFG_DENALI_PI_94
  [24] PI_DATA_BYTE_SWAP_SLICE1 — DATA pin 1 mux selector
  [16] PI_DATA_BYTE_SWAP_SLICE0 — DATA pin 0 mux selector
  [8] PI_DATA_BYTE_SWAP_EN — DATA pin swap function enable
  [4:0] PI_BANK_MUX_1 — Command pin BANK_1 mux selector
0x217C CTLPHY_WRAP__CTL_CFG__CTLCFG_DENALI_PI_95 access per field
  [25:24] PI_UPDATE_ERROR_STATUS ro — Identifies the source of any DFI PI-initiated update errors. Value of 1 indicates a timing violation of the associated timing parameter. Bit 1-0: ctrlupd_max_error, ctrlupd_interval_error. Bit 6-2: reserved. READ-ONLY
  [23:8] PI_TDFI_CTRLUPD_MIN rw — Reports the DFI tCTRLUPD_MIN timing parameter [in DFI clocks], the minimum cycles that dfi_ctrlupd_req must be asserted.
  [0] PI_CTRLUPD_REQ_PER_AREF_EN rw — Enable an automatic PI initiated update [dfi_ctrlupd_req] after every refresh. Set to 1 to enable.
0x2180 CTLPHY_WRAP__CTL_CFG__CTLCFG_DENALI_PI_96 access per field
  [24] PI_BIST_LFSR_PATTERN_DONE ro — BIST operation lfsr pattern, data pattern 1'b0 means the data is useful,1'b1 means next pattern sequence can ingore. READ-ONLY
  [17:16] PI_BIST_RESULT ro — BIST operation status [pass/fail]. Bit [0] indicates data check status and bit [1] indicates address check status. Value of 1 is a passing result. READ-ONLY
  [8] PI_BIST_GO rw — Initiate a BIST operation. Set to 1 to trigger.
  [2:0] PI_TDFI_PARIN_LAT rw — Defines the DFI tPARIN_LAT timing parameter [in DFI PHY clocks], the maximum cycles between a DFI command and a dfi_parity_in signal assertion.
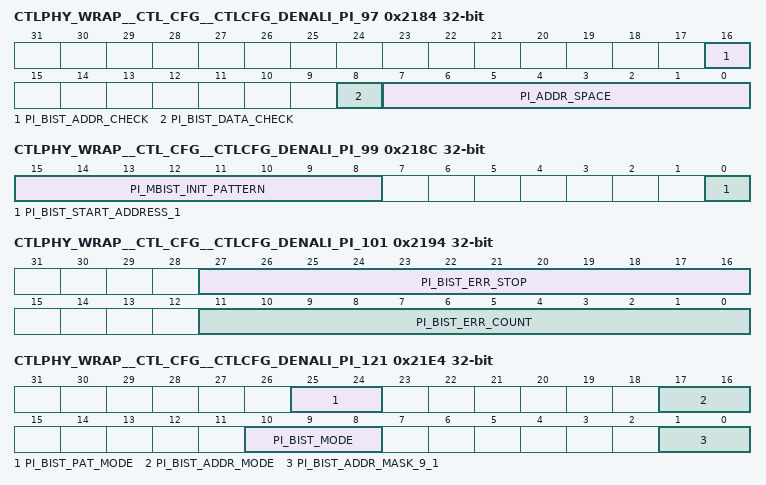
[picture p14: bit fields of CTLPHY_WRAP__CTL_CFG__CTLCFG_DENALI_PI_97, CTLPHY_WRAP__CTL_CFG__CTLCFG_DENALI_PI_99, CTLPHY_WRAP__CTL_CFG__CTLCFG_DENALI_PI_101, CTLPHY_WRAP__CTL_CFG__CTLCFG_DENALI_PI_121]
0x2184 CTLPHY_WRAP__CTL_CFG__CTLCFG_DENALI_PI_97
  [16] PI_BIST_ADDR_CHECK — Enable address checking with BIST operation. Set to 1 to enable.
  [8] PI_BIST_DATA_CHECK — Enable data checking with BIST operation. Set to 1 to enable.
  [7:0] PI_ADDR_SPACE — Sets the number of address bits to check during BIST operation. The end address of BIST is start_address+[1 shifted up by PI_ADDR_SPACE]-1. The end address should not beyond the actual memory address range.
0x2188 CTLPHY_WRAP__CTL_CFG__CTLCFG_DENALI_PI_98
  [31:0] PI_BIST_START_ADDRESS_0 — Start BIST checking at this address.
0x218C CTLPHY_WRAP__CTL_CFG__CTLCFG_DENALI_PI_99
  [15:8] PI_MBIST_INIT_PATTERN — PI mbist data check, random lfsr pattern mode init pattern seed.
  [0] PI_BIST_START_ADDRESS_1 — Start BIST checking at this address.
0x2190 CTLPHY_WRAP__CTL_CFG__CTLCFG_DENALI_PI_100
  [31:0] PI_BIST_DATA_MASK — Mask applied to data for BIST error checking. Bit [0] controls memory data path bit [0], bit [1] controls memory data path bit [1], etc. The mask range is the data transfer size in each memory clock cycle [The data on a rising edge and a failing edge]. Set each bit to 1 to mask.
0x2194 CTLPHY_WRAP__CTL_CFG__CTLCFG_DENALI_PI_101 access per field
  [27:16] PI_BIST_ERR_STOP rw — Defines the maximum number of error occurrences allowed prior to quitting when the BIST_TEST_MODE parameter is set to 1, 2 or 3. A value of 0 will allow the test to run to completion.
  [11:0] PI_BIST_ERR_COUNT ro — Indicates the number of BIST errors found when the BIST_TEST_MODE parameter is set to 1, 2 or 3. READ-ONLY
0x2198 CTLPHY_WRAP__CTL_CFG__CTLCFG_DENALI_PI_102
  [31:0] PI_BIST_ADDR_MASK_0_0 — Defines an address to be masked during the BIST operation..
0x219C CTLPHY_WRAP__CTL_CFG__CTLCFG_DENALI_PI_103
  [1:0] PI_BIST_ADDR_MASK_0_1 — Defines an address to be masked during the BIST operation..
0x21A0 CTLPHY_WRAP__CTL_CFG__CTLCFG_DENALI_PI_104
  [31:0] PI_BIST_ADDR_MASK_1_0 — Defines an address to be masked during the BIST operation..
0x21A4 CTLPHY_WRAP__CTL_CFG__CTLCFG_DENALI_PI_105
  [1:0] PI_BIST_ADDR_MASK_1_1 — Defines an address to be masked during the BIST operation..
0x21A8 CTLPHY_WRAP__CTL_CFG__CTLCFG_DENALI_PI_106
  [31:0] PI_BIST_ADDR_MASK_2_0 — Defines an address to be masked during the BIST operation..
0x21AC CTLPHY_WRAP__CTL_CFG__CTLCFG_DENALI_PI_107
  [1:0] PI_BIST_ADDR_MASK_2_1 — Defines an address to be masked during the BIST operation..
0x21B0 CTLPHY_WRAP__CTL_CFG__CTLCFG_DENALI_PI_108
  [31:0] PI_BIST_ADDR_MASK_3_0 — Defines an address to be masked during the BIST operation..
0x21B4 CTLPHY_WRAP__CTL_CFG__CTLCFG_DENALI_PI_109
  [1:0] PI_BIST_ADDR_MASK_3_1 — Defines an address to be masked during the BIST operation..
0x21B8 CTLPHY_WRAP__CTL_CFG__CTLCFG_DENALI_PI_110
  [31:0] PI_BIST_ADDR_MASK_4_0 — Defines an address to be masked during the BIST operation..
0x21BC CTLPHY_WRAP__CTL_CFG__CTLCFG_DENALI_PI_111
  [1:0] PI_BIST_ADDR_MASK_4_1 — Defines an address to be masked during the BIST operation..
0x21C0 CTLPHY_WRAP__CTL_CFG__CTLCFG_DENALI_PI_112
  [31:0] PI_BIST_ADDR_MASK_5_0 — Defines an address to be masked during the BIST operation..
0x21C4 CTLPHY_WRAP__CTL_CFG__CTLCFG_DENALI_PI_113
  [1:0] PI_BIST_ADDR_MASK_5_1 — Defines an address to be masked during the BIST operation..
0x21C8 CTLPHY_WRAP__CTL_CFG__CTLCFG_DENALI_PI_114
  [31:0] PI_BIST_ADDR_MASK_6_0 — Defines an address to be masked during the BIST operation..
0x21CC CTLPHY_WRAP__CTL_CFG__CTLCFG_DENALI_PI_115
  [1:0] PI_BIST_ADDR_MASK_6_1 — Defines an address to be masked during the BIST operation..
0x21D0 CTLPHY_WRAP__CTL_CFG__CTLCFG_DENALI_PI_116
  [31:0] PI_BIST_ADDR_MASK_7_0 — Defines an address to be masked during the BIST operation..
0x21D4 CTLPHY_WRAP__CTL_CFG__CTLCFG_DENALI_PI_117
  [1:0] PI_BIST_ADDR_MASK_7_1 — Defines an address to be masked during the BIST operation..
0x21D8 CTLPHY_WRAP__CTL_CFG__CTLCFG_DENALI_PI_118
  [31:0] PI_BIST_ADDR_MASK_8_0 — Defines an address to be masked during the BIST operation..
0x21DC CTLPHY_WRAP__CTL_CFG__CTLCFG_DENALI_PI_119
  [1:0] PI_BIST_ADDR_MASK_8_1 — Defines an address to be masked during the BIST operation..
0x21E0 CTLPHY_WRAP__CTL_CFG__CTLCFG_DENALI_PI_120
  [31:0] PI_BIST_ADDR_MASK_9_0 — Defines an address to be masked during the BIST operation..
0x21E4 CTLPHY_WRAP__CTL_CFG__CTLCFG_DENALI_PI_121
  [25:24] PI_BIST_PAT_MODE — Sets the pattern mode of BIST. 'b00 indicates using built-in pattern. 'b01 indicates checkerboard pattern, each data transfer inverts the last data transfer based on the built-in pattern. 'b10 indicates using both user pattern and built-in pattern. 'b11 indicates using pi lfsr random pattern.
  [17:16] PI_BIST_ADDR_MODE — Sets the address traversing order of BIST. 'b00 indicates fast column order [burst-column-bank-row-rank]. 'b01 indicates fast row order [burst-row-column-bank-rank]. 'b10 indicates fast bank order [burst-bank-column-row-rank].
  [10:8] PI_BIST_MODE — Sets the BIST data checking mode. 'b00 indicates MOVI13N mode. 'b01 indicates March C mode. 'b10 indicates GALPAT mode. 'b11 indicates PRBS mode. 'b100 indicates programmable March data check mode.
  [1:0] PI_BIST_ADDR_MASK_9_1 — Defines an address to be masked during the BIST operation..
0x21E8 CTLPHY_WRAP__CTL_CFG__CTLCFG_DENALI_PI_122
  [31:0] PI_BIST_USER_PAT_0 — Sets the user-specified pattern of BIST.
0x21EC CTLPHY_WRAP__CTL_CFG__CTLCFG_DENALI_PI_123
  [31:0] PI_BIST_USER_PAT_1 — Sets the user-specified pattern of BIST.
0x21F0 CTLPHY_WRAP__CTL_CFG__CTLCFG_DENALI_PI_124
  [5:0] PI_BIST_PAT_NUM — Sets the max used pattern number of BIST from a total of 8 built-in patterns. Ex. set to 3, The BIST would use pattern 1, 2 and 3.
{0x2000+4i} CTLPHY_WRAP__CTL_CFG__CTLCFG_DENALI_PI_{i} (i=125..132)
  [29:0] PI_BIST_STAGE_{i-125} — Sets the programmable algorithm of each stage X when pi_bist_mmode = 'h4.
0x2214 CTLPHY_WRAP__CTL_CFG__CTLCFG_DENALI_PI_133
  [24] PI_SELF_REFRESH_EN — Control for PI to enable self refresh mode. Set to 1 to enable.
  [16] PI_CRC_CALC — Defines where CRC is performed; set to 1 for PI responsibility or clear to 0 for PHY responsibility.
  [8] PI_BG_ROTATE_EN — Enable bank group rotation. Set to 1 to enable.
  [3:0] PI_COL_DIFF — Difference between number of column pins available and number being used.
0x2218 CTLPHY_WRAP__CTL_CFG__CTLCFG_DENALI_PI_134 access per field
  [24] PI_SREF_ENTRY_REQ wo — In PI power up data retention, PI can issued sref entry command. WRITE-ONLY
  [16] PI_SREFRESH_EXIT_NO_REFRESH rw — Disables the automatic refresh request associated with self-refresh exit. Set to 1 to disable.
  [8] PI_PWRUP_SREFRESH_EXIT rw — PI control powerup via self-refresh instead of full memory initialization. Set to 1 to enable.
  [0] PI_MC_PWRUP_SREFRESH_EXIT rw — It indicates MC control powerup via self-refresh instead of full memory initialization. Set to 1 to enable.
0x221C CTLPHY_WRAP__CTL_CFG__CTLCFG_DENALI_PI_135
  [24] PI_NO_AUTO_MRR_INIT — Disable MRR commands during initialization. Set to 1 to disable.
  [16] PI_NO_PHY_IND_TRAIN_INIT — Disable PHY Independent Training during initialization. Set to 1 to disable.
  [8] PI_NO_MRW_INIT — Disable MRW commands after training during initialization. Set to 1 to disable.
  [0] PI_NO_MRW_BT_INIT — Disable MRW commands before training during initialization. Set to 1 to disable.
0x2220 CTLPHY_WRAP__CTL_CFG__CTLCFG_DENALI_PI_136
  [31:0] PI_TRST_PWRON — Duration of memory reset during power-on initialization.
0x2224 CTLPHY_WRAP__CTL_CFG__CTLCFG_DENALI_PI_137
  [31:0] PI_CKE_INACTIVE — Number of cycles after reset before CKE will be active.
0x2228 CTLPHY_WRAP__CTL_CFG__CTLCFG_DENALI_PI_138
  [31:16] PI_DLL_RST_DELAY — Minimum cycles required for DLL reset signal dll_rst_n to be held.
  [8] PI_DRAM_INIT_EN — Control for the initialization of DRAM by the PI.
  [0] PI_DLL_RST — Enables use of the DLL reset [dll_rst_n].
0x222C CTLPHY_WRAP__CTL_CFG__CTLCFG_DENALI_PI_139
  [7:0] PI_DLL_RST_ADJ_DLY — Minimum cycles after setting master delay in DLL until the DLL reset signal dll_rst_n may be asserted.
0x2230 CTLPHY_WRAP__CTL_CFG__CTLCFG_DENALI_PI_140
  [25:0] PI_WRITE_MODEREG — Write memory mode register data to the DRAMs. Bits [7:0] define the memory mode register number if bit [23] is set, bits [15:8] define the chip select if bit [24] is clear, bits [23:16] define which memory mode register/s to write, bit [24] defines whether all chip selects will be written, and bit [25] triggers the write.
0x2234 CTLPHY_WRAP__CTL_CFG__CTLCFG_DENALI_PI_141 ro
  [7:0] PI_MRW_STATUS — Write memory mode register status. Bit [0] set indicates a WRITE_MODEREG parameter programming error. Bit [1] set indicates a PASR error. Bit [2] is Reserved. Bit [3] set indicates a self refresh or deep power down error. Bit [4] set indicates that a write to MR3 or MR11 was attempted [write_modereg bit [25] was asserted with bit [17] set, or bit [23] was asserted with bits [7:0] defining MR3 or MR11] during tZQCAL after a ZQ calibration start command. READ-ONLY
